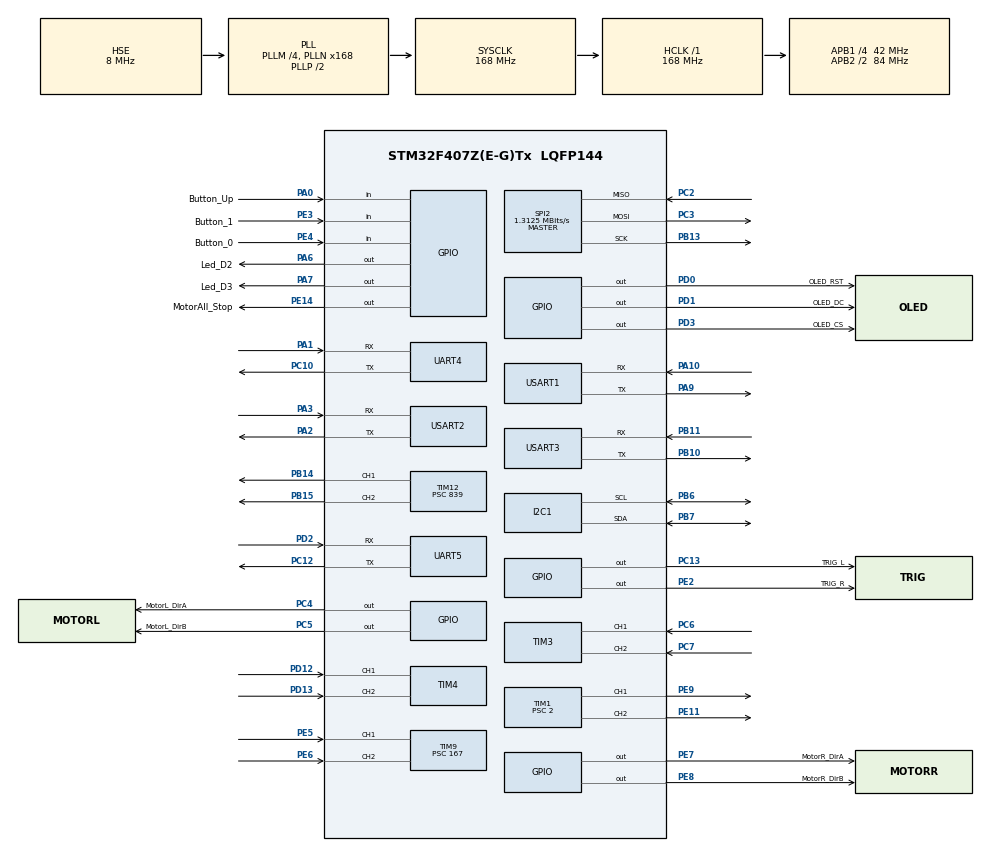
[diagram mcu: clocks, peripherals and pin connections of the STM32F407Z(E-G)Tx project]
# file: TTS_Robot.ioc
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Dma.Request0=USART1_RX
Dma.Request1=USART1_TX
Dma.USART1_RX.0.Direction=DMA_PERIPH_TO_MEMORY
Dma.USART1_RX.0.FIFOMode=DMA_FIFOMODE_DISABLE
Dma.USART1_RX.0.Instance=DMA2_Stream2
Dma.USART1_RX.0.MemDataAlignment=DMA_MDATAALIGN_BYTE
Dma.USART1_RX.0.MemInc=DMA_MINC_ENABLE
Dma.USART1_RX.0.Mode=DMA_NORMAL
Dma.USART1_RX.0.PeriphDataAlignment=DMA_PDATAALIGN_BYTE
Dma.USART1_RX.0.PeriphInc=DMA_PINC_DISABLE
Dma.USART1_RX.0.Priority=DMA_PRIORITY_LOW
Dma.USART1_TX.1.Direction=DMA_MEMORY_TO_PERIPH
Dma.USART1_TX.1.FIFOMode=DMA_FIFOMODE_DISABLE
Dma.USART1_TX.1.Instance=DMA2_Stream7
Dma.USART1_TX.1.MemDataAlignment=DMA_MDATAALIGN_BYTE
Dma.USART1_TX.1.MemInc=DMA_MINC_ENABLE
Dma.USART1_TX.1.Mode=DMA_NORMAL
Dma.USART1_TX.1.PeriphDataAlignment=DMA_PDATAALIGN_BYTE
Dma.USART1_TX.1.PeriphInc=DMA_PINC_DISABLE
Dma.USART1_TX.1.Priority=DMA_PRIORITY_LOW
Mcu.Family=STM32F4
Mcu.Name=STM32F407Z(E-G)Tx
Mcu.Package=LQFP144
NVIC.DMA2_Stream2_IRQn=true\:0\:0\:false\:false\:true\:false\:true\:true
NVIC.DMA2_Stream7_IRQn=true\:0\:0\:false\:false\:true\:false\:true\:true
NVIC.I2C1_ER_IRQn=true\:0\:0\:false\:false\:true\:true\:true\:true
NVIC.I2C1_EV_IRQn=true\:0\:0\:false\:false\:true\:true\:true\:true
NVIC.PriorityGroup=NVIC_PRIORITYGROUP_4
NVIC.SPI2_IRQn=true\:0\:0\:false\:false\:true\:true\:true\:true
NVIC.TIM1_BRK_TIM9_IRQn=true\:0\:0\:false\:false\:true\:true\:true\:true
NVIC.TIM3_IRQn=true\:0\:0\:false\:false\:true\:true\:true\:true
NVIC.TIM4_IRQn=true\:0\:0\:false\:false\:true\:true\:true\:true
NVIC.TIM6_DAC_IRQn=true\:0\:0\:false\:false\:true\:true\:true\:true
NVIC.UART4_IRQn=true\:0\:0\:false\:false\:true\:true\:true\:true
NVIC.UART5_IRQn=true\:0\:0\:false\:false\:true\:true\:true\:true
NVIC.USART1_IRQn=true\:0\:0\:false\:false\:true\:true\:true\:true
NVIC.USART2_IRQn=true\:0\:0\:false\:false\:true\:true\:true\:true
NVIC.USART3_IRQn=true\:0\:0\:false\:false\:true\:true\:true\:true
PA0-WKUP.GPIO_Label=Button_Up
PA0-WKUP.GPIO_PuPd=GPIO_PULLDOWN
PA0-WKUP.Signal=GPIO_Input
PA1.Mode=Asynchronous
PA1.Signal=UART4_RX
PA10.Mode=Asynchronous
PA10.Signal=USART1_RX
PA13.Mode=JTAG_5_pins
PA13.Signal=SYS_JTMS-SWDIO
PA14.Mode=JTAG_5_pins
PA14.Signal=SYS_JTCK-SWCLK
PA15.Mode=JTAG_5_pins
PA15.Signal=SYS_JTDI
PA2.Mode=Asynchronous
PA2.Signal=USART2_TX
PA3.Mode=Asynchronous
PA3.Signal=USART2_RX
PA6.GPIO_Label=Led_D2
PA6.GPIO_ModeDefaultOutputPP=GPIO_MODE_OUTPUT_PP
PA6.GPIO_PuPd=GPIO_NOPULL
PA6.GPIO_Speed=GPIO_SPEED_FREQ_VERY_HIGH
PA6.PinState=GPIO_PIN_SET
PA6.Signal=GPIO_Output
PA7.GPIO_Label=Led_D3
PA7.GPIO_ModeDefaultOutputPP=GPIO_MODE_OUTPUT_PP
PA7.GPIO_PuPd=GPIO_NOPULL
PA7.GPIO_Speed=GPIO_SPEED_FREQ_VERY_HIGH
PA7.PinState=GPIO_PIN_SET
PA7.Signal=GPIO_Output
PA9.Mode=Asynchronous
PA9.Signal=USART1_TX
PB10.Mode=Asynchronous
PB10.Signal=USART3_TX
PB11.Mode=Asynchronous
PB11.Signal=USART3_RX
PB13.Mode=Full_Duplex_Master
PB13.Signal=SPI2_SCK
PB14.Signal=S_TIM12_CH1
PB15.Signal=S_TIM12_CH2
PB3.Mode=JTAG_5_pins
PB3.Signal=SYS_JTDO-SWO
PB4.Mode=JTAG_5_pins
PB4.Signal=SYS_JTRST
PB6.Mode=I2C
PB6.Signal=I2C1_SCL
PB7.Mode=I2C
PB7.Signal=I2C1_SDA
PC10.Mode=Asynchronous
PC10.Signal=UART4_TX
PC12.Mode=Asynchronous
PC12.Signal=UART5_TX
PC13-ANTI_TAMP.GPIO_Label=TRIG_L
PC13-ANTI_TAMP.GPIO_ModeDefaultOutputPP=GPIO_MODE_OUTPUT_PP
PC13-ANTI_TAMP.GPIO_PuPd=GPIO_NOPULL
PC13-ANTI_TAMP.GPIO_Speed=GPIO_SPEED_FREQ_LOW
PC13-ANTI_TAMP.PinState=GPIO_PIN_RESET
PC13-ANTI_TAMP.Signal=GPIO_Output
PC14-OSC32_IN.Mode=LSE-External-Oscillator
PC14-OSC32_IN.Signal=RCC_OSC32_IN
PC15-OSC32_OUT.Mode=LSE-External-Oscillator
PC15-OSC32_OUT.Signal=RCC_OSC32_OUT
PC2.Mode=Full_Duplex_Master
PC2.Signal=SPI2_MISO
PC3.Mode=Full_Duplex_Master
PC3.Signal=SPI2_MOSI
PC4.GPIO_Label=MotorL_DirA
PC4.GPIO_ModeDefaultOutputPP=GPIO_MODE_OUTPUT_PP
PC4.GPIO_PuPd=GPIO_PULLDOWN
PC4.GPIO_Speed=GPIO_SPEED_FREQ_VERY_HIGH
PC4.PinState=GPIO_PIN_RESET
PC4.Signal=GPIO_Output
PC5.GPIO_Label=MotorL_DirB
PC5.GPIO_ModeDefaultOutputPP=GPIO_MODE_OUTPUT_PP
PC5.GPIO_PuPd=GPIO_PULLDOWN
PC5.GPIO_Speed=GPIO_SPEED_FREQ_VERY_HIGH
PC5.PinState=GPIO_PIN_RESET
PC5.Signal=GPIO_Output
PC6.Signal=S_TIM3_CH1
PC7.Signal=S_TIM3_CH2
PD0.GPIO_Label=OLED_RST
PD0.GPIO_ModeDefaultOutputPP=GPIO_MODE_OUTPUT_PP
PD0.GPIO_Speed=GPIO_SPEED_FREQ_VERY_HIGH
PD0.PinState=GPIO_PIN_SET
PD0.Signal=GPIO_Output
PD1.GPIO_Label=OLED_DC
PD1.GPIO_ModeDefaultOutputPP=GPIO_MODE_OUTPUT_PP
PD1.GPIO_Speed=GPIO_SPEED_FREQ_VERY_HIGH
PD1.PinState=GPIO_PIN_SET
PD1.Signal=GPIO_Output
PD12.Signal=S_TIM4_CH1
PD13.Signal=S_TIM4_CH2
PD2.Mode=Asynchronous
PD2.Signal=UART5_RX
PD3.GPIO_Label=OLED_CS
PD3.GPIO_ModeDefaultOutputPP=GPIO_MODE_OUTPUT_PP
PD3.GPIO_Speed=GPIO_SPEED_FREQ_VERY_HIGH
PD3.PinState=GPIO_PIN_SET
PD3.Signal=GPIO_Output
PE11.Signal=S_TIM1_CH2
PE14.GPIO_Label=MotorAll_Stop
PE14.GPIO_ModeDefaultOutputPP=GPIO_MODE_OUTPUT_PP
PE14.GPIO_PuPd=GPIO_PULLDOWN
PE14.GPIO_Speed=GPIO_SPEED_FREQ_VERY_HIGH
PE14.PinState=GPIO_PIN_RESET
PE14.Signal=GPIO_Output
PE2.GPIO_Label=TRIG_R
PE2.GPIO_ModeDefaultOutputPP=GPIO_MODE_OUTPUT_PP
PE2.GPIO_PuPd=GPIO_NOPULL
PE2.GPIO_Speed=GPIO_SPEED_FREQ_HIGH
PE2.PinState=GPIO_PIN_RESET
PE2.Signal=GPIO_Output
PE3.GPIO_Label=Button_1
PE3.GPIO_Mode=GPIO_MODE_INPUT
PE3.GPIO_PuPd=GPIO_PULLUP
PE3.Signal=GPIO_Input
PE4.GPIO_Label=Button_0
PE4.GPIO_Mode=GPIO_MODE_INPUT
PE4.GPIO_PuPd=GPIO_PULLUP
PE4.Signal=GPIO_Input
PE5.Signal=S_TIM9_CH1
PE6.Signal=S_TIM9_CH2
PE7.GPIO_Label=MotorR_DirA
PE7.GPIO_ModeDefaultOutputPP=GPIO_MODE_OUTPUT_PP
PE7.GPIO_PuPd=GPIO_PULLDOWN
PE7.GPIO_Speed=GPIO_SPEED_FREQ_VERY_HIGH
PE7.PinState=GPIO_PIN_RESET
PE7.Signal=GPIO_Output
PE8.GPIO_Label=MotorR_DirB
PE8.GPIO_ModeDefaultOutputPP=GPIO_MODE_OUTPUT_PP
PE8.GPIO_PuPd=GPIO_PULLDOWN
PE8.GPIO_Speed=GPIO_SPEED_FREQ_VERY_HIGH
PE8.PinState=GPIO_PIN_RESET
PE8.Signal=GPIO_Output
PE9.Signal=S_TIM1_CH1
PH0-OSC_IN.Mode=HSE-External-Oscillator
PH0-OSC_IN.Signal=RCC_OSC_IN
PH1-OSC_OUT.Mode=HSE-External-Oscillator
PH1-OSC_OUT.Signal=RCC_OSC_OUT
ProjectManager.HeapSize=0x200
ProjectManager.StackSize=0x400
ProjectManager.TargetToolchain=STM32CubeIDE
RCC.48MHZClocksFreq_Value=84000000
RCC.AHBFreq_Value=168000000
RCC.APB1CLKDivider=RCC_HCLK_DIV4
RCC.APB1Freq_Value=42000000
RCC.APB1TimFreq_Value=84000000
RCC.APB2CLKDivider=RCC_HCLK_DIV2
RCC.APB2Freq_Value=84000000
RCC.APB2TimFreq_Value=168000000
RCC.CortexFreq_Value=168000000
RCC.HCLKFreq_Value=168000000
RCC.HSE_VALUE=8000000
RCC.HSI_VALUE=16000000
RCC.PLLM=4
RCC.PLLN=168
RCC.PLLSourceVirtual=RCC_PLLSOURCE_HSE
RCC.SYSCLKFreq_VALUE=168000000
RCC.SYSCLKSource=RCC_SYSCLKSOURCE_PLLCLK
RCC.VCOOutputFreq_Value=336000000
SH.S_TIM12_CH1.0=TIM12_CH1,PWM Generation1 CH1
SH.S_TIM12_CH2.0=TIM12_CH2,PWM Generation2 CH2
SH.S_TIM1_CH1.0=TIM1_CH1,PWM Generation1 CH1
SH.S_TIM1_CH2.0=TIM1_CH2,PWM Generation2 CH2
SH.S_TIM3_CH1.0=TIM3_CH1,Encoder_Interface
SH.S_TIM3_CH2.0=TIM3_CH2,Encoder_Interface
SH.S_TIM4_CH1.0=TIM4_CH1,Encoder_Interface
SH.S_TIM4_CH2.0=TIM4_CH2,Encoder_Interface
SH.S_TIM9_CH1.0=TIM9_CH1,Input_Capture1_from_TI1
SH.S_TIM9_CH2.0=TIM9_CH2,Input_Capture2_from_TI2
SPI2.BaudRatePrescaler=SPI_BAUDRATEPRESCALER_32
SPI2.CLKPhase=SPI_PHASE_1EDGE
SPI2.CalculateBaudRate=1.3125 MBits/s
SPI2.DataSize=SPI_DATASIZE_8BIT
SPI2.Direction=SPI_DIRECTION_2LINES
SPI2.Mode=SPI_MODE_MASTER
SPI2.VirtualType=VM_MASTER
TIM1.Channel-PWM\ Generation1\ CH1=TIM_CHANNEL_1
TIM1.Channel-PWM\ Generation2\ CH2=TIM_CHANNEL_2
TIM1.Period=999
TIM1.Prescaler=2
TIM12.AutoReloadPreload=TIM_AUTORELOAD_PRELOAD_ENABLE
TIM12.Channel-PWM\ Generation1\ CH1=TIM_CHANNEL_1
TIM12.Channel-PWM\ Generation2\ CH2=TIM_CHANNEL_2
TIM12.Period=1999
TIM12.Prescaler=839
TIM12.Pulse-PWM\ Generation1\ CH1=0
TIM12.Pulse-PWM\ Generation2\ CH2=0
TIM3.EncoderMode=TIM_ENCODERMODE_TI12
TIM3.IC1Filter=2
TIM3.IC2Filter=2
TIM4.EncoderMode=TIM_ENCODERMODE_TI12
TIM4.IC1Filter=2
TIM4.IC2Filter=2
TIM6.AutoReloadPreload=TIM_AUTORELOAD_PRELOAD_ENABLE
TIM6.Period=999
TIM6.Prescaler=83
TIM9.Channel-Input_Capture1_from_TI1=TIM_CHANNEL_1
TIM9.Channel-Input_Capture2_from_TI2=TIM_CHANNEL_2
TIM9.ICFilter_CH1=8
TIM9.ICFilter_CH2=8
TIM9.Prescaler=167
UART4.VirtualMode=Asynchronous
UART5.VirtualMode=Asynchronous
USART1.VirtualMode=VM_ASYNC
USART2.VirtualMode=VM_ASYNC
USART3.VirtualMode=VM_ASYNC
VP_TIM12_VS_ClockSourceINT.Mode=Internal
VP_TIM1_VS_ClockSourceINT.Mode=Internal
VP_TIM6_VS_ClockSourceINT.Mode=Enable_Timer
VP_TIM9_VS_ClockSourceINT.Mode=Internal
board=custom

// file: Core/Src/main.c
/* USER CODE BEGIN Header */
/**
  ******************************************************************************
  * @file           : main.c
  * @brief          : Main program body
  ******************************************************************************
  * @attention
  *
  * Copyright (c) 2023 STMicroelectronics.
  * All rights reserved.
  *
  * This software is licensed under terms that can be found in the LICENSE file
  * in the root directory of this software component.
  * If no LICENSE file comes with this software, it is provided AS-IS.
  *
  ******************************************************************************
  */
/* USER CODE END Header */
#include "main.h"
#include "dma.h"
#include "i2c.h"
#include "spi.h"
#include "tim.h"
#include "usart.h"
#include "gpio.h"

/* USER CODE BEGIN Includes */
#include "../User/User.h"
/* USER CODE END Includes */

void SystemClock_Config(void);

int main(void)
{

  /* MCU Configuration--------------------------------------------------------*/

  /* Reset of all peripherals, Initializes the Flash interface and the Systick. */
  HAL_Init();

  /* Configure the system clock */
  SystemClock_Config();

  /* Initialize all configured peripherals */
  MX_GPIO_Init();
  MX_DMA_Init();
  MX_TIM1_Init();
  MX_TIM3_Init();
  MX_TIM4_Init();
  MX_TIM6_Init();
  MX_TIM9_Init();
  MX_TIM12_Init();
  MX_I2C1_Init();
  MX_UART4_Init();
  MX_USART1_UART_Init();
  MX_USART2_UART_Init();
  MX_USART3_UART_Init();
  MX_UART5_Init();
  MX_SPI2_Init();
  /* USER CODE BEGIN 2 */
  hal_CPUInit();
  User_Bsp_Init();
  User_Create_task();
  TTS_Start();
  /* USER CODE END 2 */

  /* Infinite loop */
  /* USER CODE BEGIN WHILE */
  while (1)
  {
    HAL_GPIO_TogglePin(Led_D3_GPIO_Port,Led_D3_Pin);
    HAL_Delay(100);
    /* USER CODE END WHILE */

  }
}

void SystemClock_Config(void)
{
  RCC_OscInitTypeDef RCC_OscInitStruct = {0};
  RCC_ClkInitTypeDef RCC_ClkInitStruct = {0};

  /** Configure the main internal regulator output voltage
  */
  __HAL_RCC_PWR_CLK_ENABLE();
  __HAL_PWR_VOLTAGESCALING_CONFIG(PWR_REGULATOR_VOLTAGE_SCALE1);

  /** Initializes the RCC Oscillators according to the specified parameters
  * in the RCC_OscInitTypeDef structure.
  */
  RCC_OscInitStruct.OscillatorType = RCC_OSCILLATORTYPE_HSE;
  RCC_OscInitStruct.HSEState = RCC_HSE_ON;
  RCC_OscInitStruct.PLL.PLLState = RCC_PLL_ON;
  RCC_OscInitStruct.PLL.PLLSource = RCC_PLLSOURCE_HSE;
  RCC_OscInitStruct.PLL.PLLM = 4;
  RCC_OscInitStruct.PLL.PLLN = 168;
  RCC_OscInitStruct.PLL.PLLP = RCC_PLLP_DIV2;
  RCC_OscInitStruct.PLL.PLLQ = 4;
  if (HAL_RCC_OscConfig(&RCC_OscInitStruct) != HAL_OK)
  {
    Error_Handler();
  }

  /** Initializes the CPU, AHB and APB buses clocks
  */
  RCC_ClkInitStruct.ClockType = RCC_CLOCKTYPE_HCLK|RCC_CLOCKTYPE_SYSCLK
                              |RCC_CLOCKTYPE_PCLK1|RCC_CLOCKTYPE_PCLK2;
  RCC_ClkInitStruct.SYSCLKSource = RCC_SYSCLKSOURCE_PLLCLK;
  RCC_ClkInitStruct.AHBCLKDivider = RCC_SYSCLK_DIV1;
  RCC_ClkInitStruct.APB1CLKDivider = RCC_HCLK_DIV4;
  RCC_ClkInitStruct.APB2CLKDivider = RCC_HCLK_DIV2;

  if (HAL_RCC_ClockConfig(&RCC_ClkInitStruct, FLASH_LATENCY_5) != HAL_OK)
  {
    Error_Handler();
  }
}

void Error_Handler(void)
{
  __disable_irq();
  while (1)
  {
  }
}
